# ATSAML21E15B device description
Architecture: CORTEX-M0PLUS; Family: SAML; Series: SAML21
Registers are 32-bit, read-write, reset 0x0 unless marked. A register's access mark holds for its fields unless they carry their own. Offsets are from the block's base; [hi:lo] are bit positions; {n}, {i} and the like mark numbered series; 'fields as' and 'values as' point back to an identical list.

## MCLK — Main Clock
Instances: MCLK 0x40000400
0x00 CTRLA 8-bit — Control A
0x01 INTENCLR 8-bit (atomic clear) — Interrupt Enable Clear
  [0] CKRDY — Clock Ready Interrupt Enable
0x02 INTENSET 8-bit (atomic set) — Interrupt Enable Set
  [0] CKRDY — Clock Ready Interrupt Enable
0x03 INTFLAG 8-bit reset 0x1 (atomic clear) — Interrupt Flag Status and Clear
  [0] CKRDY — Clock Ready
0x04 CPUDIV 8-bit reset 0x1 — CPU Clock Division
  [7:0] CPUDIV — CPU Clock Division Factor
    1=DIV1 (Divide by 1); 2=DIV2 (Divide by 2); 4=DIV4 (Divide by 4); 8=DIV8 (Divide by 8); 16=DIV16 (Divide by 16); 32=DIV32 (Divide by 32); 64=DIV64 (Divide by 64); 128=DIV128 (Divide by 128)
0x05 LPDIV 8-bit reset 0x1 — Low-Power Clock Division
  [7:0] LPDIV — Low-Power Clock Division Factor
    values as CPUDIV.CPUDIV
0x06 BUPDIV 8-bit reset 0x1 — Backup Clock Division
  [7:0] BUPDIV — Backup Clock Division Factor
    values as CPUDIV.CPUDIV
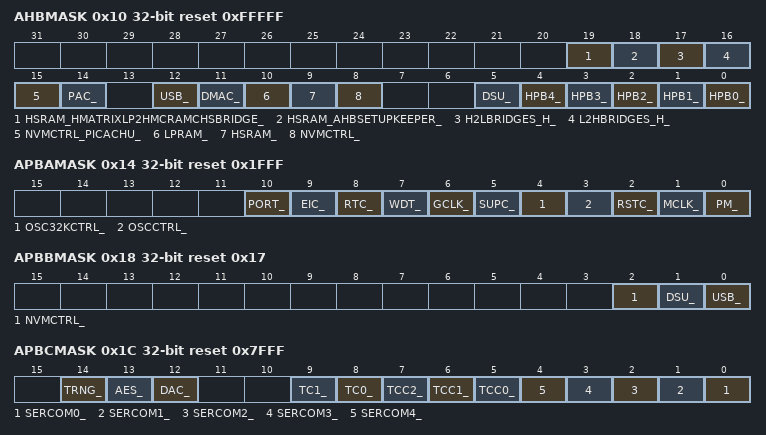
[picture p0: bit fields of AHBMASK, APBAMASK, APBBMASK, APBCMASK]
0x10 AHBMASK reset 0xFFFFF
  [19] HSRAM_HMATRIXLP2HMCRAMCHSBRIDGE_ — HSRAM_HMATRIXLP2HMCRAMCHSBRIDGE AHB Clock Mask
  [18] HSRAM_AHBSETUPKEEPER_ — HSRAM_AHBSETUPKEEPER AHB Clock Mask
  [17] H2LBRIDGES_H_ — H2LBRIDGES_H AHB Clock Mask
  [16] L2HBRIDGES_H_ — L2HBRIDGES_H AHB Clock Mask
  [15] NVMCTRL_PICACHU_ — NVMCTRL_PICACHU AHB Clock Mask
  [14] PAC_ — PAC AHB Clock Mask
  [12] USB_ — USB AHB Clock Mask
  [11] DMAC_ — DMAC AHB Clock Mask
  [10] LPRAM_ — LPRAM AHB Clock Mask
  [9] HSRAM_ — HSRAM AHB Clock Mask
  [8] NVMCTRL_ — NVMCTRL AHB Clock Mask
  [5] DSU_ — DSU AHB Clock Mask
  [n] HPB{n}_ (n=0..4) — HPB{n} AHB Clock Mask
0x14 APBAMASK reset 0x1FFF
  [10] PORT_ — PORT APB Clock Enable
  [9] EIC_ — EIC APB Clock Enable
  [8] RTC_ — RTC APB Clock Enable
  [7] WDT_ — WDT APB Clock Enable
  [6] GCLK_ — GCLK APB Clock Enable
  [5] SUPC_ — SUPC APB Clock Enable
  [4] OSC32KCTRL_ — OSC32KCTRL APB Clock Enable
  [3] OSCCTRL_ — OSCCTRL APB Clock Enable
  [2] RSTC_ — RSTC APB Clock Enable
  [1] MCLK_ — MCLK APB Clock Enable
  [0] PM_ — PM APB Clock Enable
0x18 APBBMASK reset 0x17
  [2] NVMCTRL_ — NVMCTRL APB Clock Enable
  [1] DSU_ — DSU APB Clock Enable
  [0] USB_ — USB APB Clock Enable
0x1C APBCMASK reset 0x7FFF
  [14] TRNG_ — TRNG APB Clock Enable
  [13] AES_ — AES APB Clock Enable
  [12] DAC_ — DAC APB Clock Enable
  [9] TC1_ — TC1 APB Clock Enable
  [8] TC0_ — TC0 APB Clock Enable
  [7] TCC2_ — TCC2 APB Clock Enable
  [6] TCC1_ — TCC1 APB Clock Enable
  [5] TCC0_ — TCC0 APB Clock Enable
  [n] SERCOM{n}_ (n=0..4) — SERCOM{n} APB Clock Enable
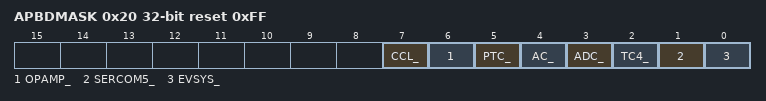
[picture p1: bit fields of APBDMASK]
0x20 APBDMASK reset 0xFF
  [7] CCL_ — CCL APB Clock Enable
  [6] OPAMP_ — OPAMP APB Clock Enable
  [5] PTC_ — PTC APB Clock Enable
  [4] AC_ — AC APB Clock Enable
  [3] ADC_ — ADC APB Clock Enable
  [2] TC4_ — TC4 APB Clock Enable
  [1] SERCOM5_ — SERCOM5 APB Clock Enable
  [0] EVSYS_ — EVSYS APB Clock Enable
0x24 APBEMASK reset 0xD
  [0] PAC_ — PAC APB Clock Enable

## MTB — Cortex-M0+ Micro-Trace Buffer
Instances: MTB 0x41006000
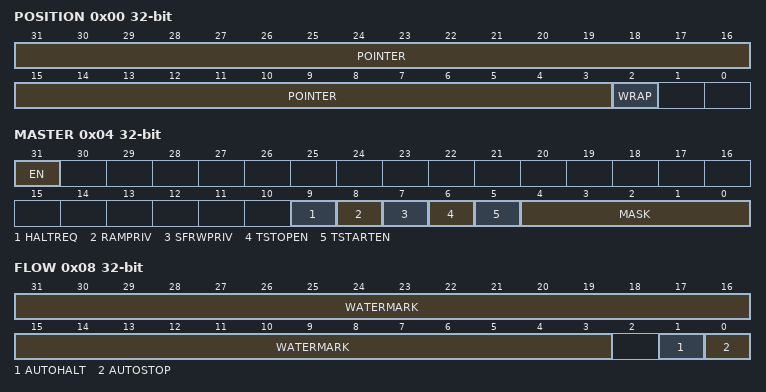
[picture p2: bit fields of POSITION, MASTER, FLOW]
0x00 POSITION reset not defined — MTB Position
  [31:3] POINTER — Trace Packet Location Pointer
  [2] WRAP — Pointer Value Wraps
0x04 MASTER — MTB Master
  [31] EN — Main Trace Enable
  [9] HALTREQ — Halt Request
  [8] RAMPRIV — SRAM Privilege
  [7] SFRWPRIV — Special Function Register Write Privilege
  [6] TSTOPEN — Trace Stop Input Enable
  [5] TSTARTEN — Trace Start Input Enable
  [4:0] MASK — Maximum Value of the Trace Buffer in SRAM
0x08 FLOW — MTB Flow
  [31:3] WATERMARK — Watermark value
  [1] AUTOHALT — Auto Halt Request
  [0] AUTOSTOP — Auto Stop Tracing
0x0C BASE ro reset not defined — MTB Base
0xF00 ITCTRL reset not defined — MTB Integration Mode Control
0xFA0 CLAIMSET reset not defined (atomic set) — MTB Claim Set
0xFA4 CLAIMCLR reset not defined (atomic clear) — MTB Claim Clear
0xFB0 LOCKACCESS reset not defined — MTB Lock Access
0xFB4 LOCKSTATUS ro reset not defined — MTB Lock Status
0xFB8 AUTHSTATUS ro reset not defined — MTB Authentication Status
0xFBC DEVARCH ro reset not defined — MTB Device Architecture
0xFC8 DEVID ro reset not defined — MTB Device Configuration
0xFCC DEVTYPE ro reset not defined — MTB Device Type
{0xFC0+4i} PID{i} ro reset not defined (i=4..7) — Peripheral Identification {i}
{0xFE0+4i} PID{i} ro reset not defined (i=0..3) — Peripheral Identification {i}
{0xFF0+4i} CID{i} ro reset not defined (i=0..3) — Component Identification {i}

## Notices in the file
Copyright (c) 2018 Microchip Technology Inc.
SPDX-License-Identifier: Apache-2.0
Licensed under the Apache License, Version 2.0 (the "License");
you may not use this file except in compliance with the License.
You may obtain a copy of the License at
http://www.apache.org/licenses/LICENSE-2.0
Unless required by applicable law or agreed to in writing, software
distributed under the License is distributed on an "AS IS" BASIS,
WITHOUT WARRANTIES OR CONDITIONS OF ANY KIND, either express or implied.
See the License for the specific language governing permissions and
limitations under the License.
